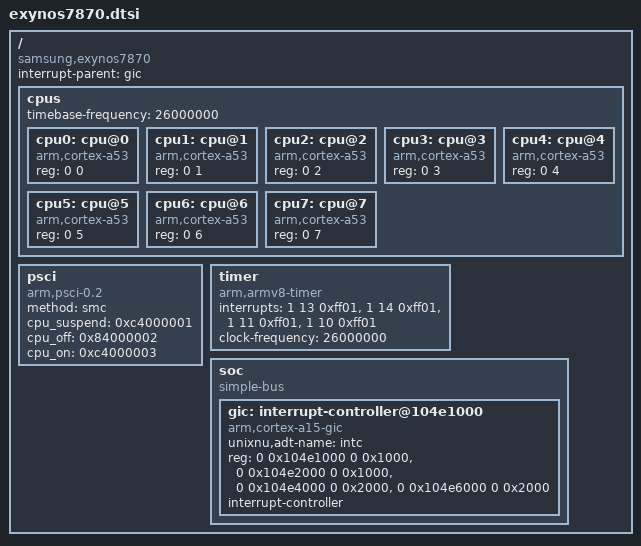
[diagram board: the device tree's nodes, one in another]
// SPDX-License-Identifier: BSD-2-Clause-Patent
//
// Shared Exynos 7870 (S5E7870) resources.
//
// Values come from the mainline Linux Exynos 7870 SoC DTSI and the
// gtaxlwifi board tree in linux-exynos7870 (soc.toml pins the revision):
//   - eight Cortex-A53 cores, MPIDR 0x000-0x007
//   - GIC-400 at 0x104e1000 (GICD), 0x104e2000 (GICC),
//     0x104e4000 (GICH), 0x104e6000 (GICV)
//   - architectural timer, 26 MHz; S-Boot does not program CNTFRQ_EL0
//   - PSCI 0.2 over SMC
//
// Board memory, reservations and enabled CPUs live in the device repository.
// The first bring-up enables cpu0 only; the other cores are added after XNU
// reaches its entry checkpoint.

/ {
    compatible = "samsung,exynos7870";
    #address-cells = <2>;
    #size-cells = <2>;
    interrupt-parent = <&gic>;

    cpus {
        #address-cells = <2>;
        #size-cells = <0>;
        timebase-frequency = <26000000>;

        cpu0: cpu@0 { device_type = "cpu"; compatible = "arm,cortex-a53", "arm,armv8"; reg = <0 0>; };
        cpu1: cpu@1 { device_type = "cpu"; compatible = "arm,cortex-a53", "arm,armv8"; reg = <0 1>; };
        cpu2: cpu@2 { device_type = "cpu"; compatible = "arm,cortex-a53", "arm,armv8"; reg = <0 2>; };
        cpu3: cpu@3 { device_type = "cpu"; compatible = "arm,cortex-a53", "arm,armv8"; reg = <0 3>; };
        cpu4: cpu@4 { device_type = "cpu"; compatible = "arm,cortex-a53", "arm,armv8"; reg = <0 4>; };
        cpu5: cpu@5 { device_type = "cpu"; compatible = "arm,cortex-a53", "arm,armv8"; reg = <0 5>; };
        cpu6: cpu@6 { device_type = "cpu"; compatible = "arm,cortex-a53", "arm,armv8"; reg = <0 6>; };
        cpu7: cpu@7 { device_type = "cpu"; compatible = "arm,cortex-a53", "arm,armv8"; reg = <0 7>; };
    };

    psci {
        compatible = "arm,psci-0.2";
        method = "smc";
        cpu_suspend = <0xc4000001>;
        cpu_off = <0x84000002>;
        cpu_on = <0xc4000003>;
    };

    timer {
        compatible = "arm,armv8-timer";
        interrupts = <1 13 0xff01>, <1 14 0xff01>, <1 11 0xff01>, <1 10 0xff01>;
        clock-frequency = <26000000>;
    };

    soc {
        compatible = "simple-bus";
        #address-cells = <2>;
        #size-cells = <2>;
        ranges;

        gic: interrupt-controller@104e1000 {
            compatible = "arm,cortex-a15-gic";
            unixnu,adt-name = "intc";
            reg = <0 0x104e1000 0 0x1000>,
                  <0 0x104e2000 0 0x1000>,
                  <0 0x104e4000 0 0x2000>,
                  <0 0x104e6000 0 0x2000>;
            #interrupt-cells = <3>;
            #address-cells = <0>;
            interrupt-controller;
            // No interrupts property here. XNU's IODTFindInterruptParent()
            // returns NULL for a node that is itself an interrupt controller,
            // and IODTGetICellCounts(NULL) then faults on address 0 while
            // IOPlatformExpertDevice::init walks the ADT. The GIC maintenance
            // PPI (9) is not used by the bring-up; add it with a self-parent
            // only after the IOKit path handles controllers with their own
            // interrupt specifiers.
        };

        // DWMMC (eMMC) at 0x13540000, DECON at 0x14830000, the Mali-T830 at
        // 0x11400000 and the debug UART at 0x13820000 are added with their
        // drivers. They are deliberately absent from the first ADT: an
        // exported node with no driver only adds probe noise.
    };
};
